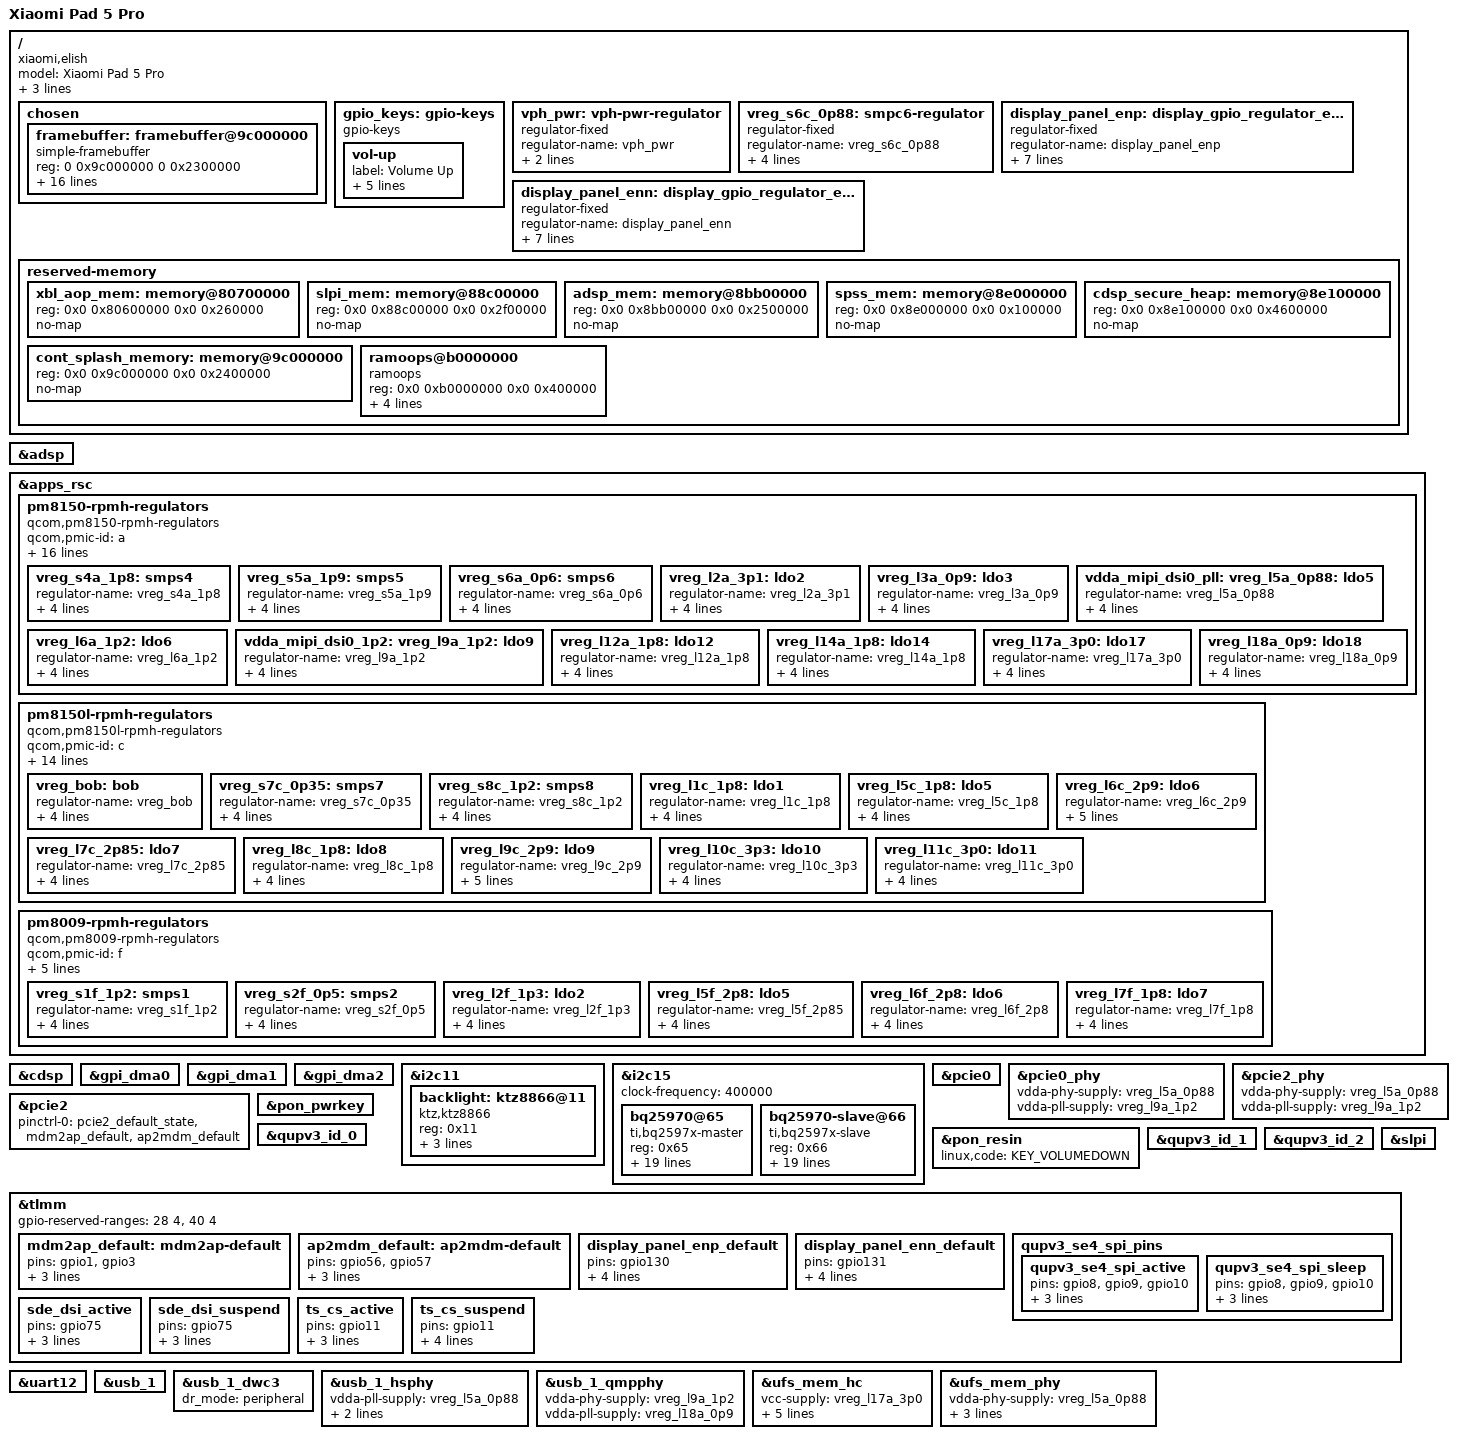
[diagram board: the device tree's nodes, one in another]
// SPDX-License-Identifier: BSD-3-Clause
/*
 * Copyright (c) 2020, The Linux Foundation. All rights reserved.
 */

/dts-v1/;

#include <dt-bindings/regulator/qcom,rpmh-regulator.h>
#include <dt-bindings/gpio/gpio.h>
#include "sm8250.dtsi"
#include "pm8150.dtsi"
#include "pm8150b.dtsi"
#include "pm8150l.dtsi"
#include "pm8009.dtsi"

/*
 * Delete following upstream (sm8250.dtsi) reserved
 * memory mappings which are different in this device.
 */
/delete-node/ &xbl_aop_mem;
/delete-node/ &slpi_mem;
/delete-node/ &adsp_mem;
/delete-node/ &spss_mem;
/delete-node/ &cdsp_secure_heap;

/ {
	model = "Xiaomi Pad 5 Pro";
	compatible = "xiaomi,elish", "qcom,sm8250";
	classis-type = "tablet";

	/* required for bootloader to select correct board */
	qcom,msm-id = <356 0x20001>; /* SM8250 v2.1 */
	qcom,board-id = <0x10008 0>;

	chosen {
		#address-cells = <2>;
		#size-cells = <2>;
		ranges;

		framebuffer: framebuffer@9c000000 {
			compatible = "simple-framebuffer";
			reg = <0 0x9c000000 0 0x2300000>;
			width = <1600>;
			height = <2560>;
			stride = <(1600 * 4)>;
			format = "a8r8g8b8";
			enp-supply = <&display_panel_enp>;
			enn-supply = <&display_panel_enn>;
			/*
			 * That's a lot of clocks, but it's necessary due
			 * to unused clk cleanup & no panel driver yet..
			 */
			clocks = <&dispcc DISP_CC_MDSS_AHB_CLK>,
				 <&gcc GCC_DISP_HF_AXI_CLK>,
				 <&gcc GCC_DISP_SF_AXI_CLK>,
				 <&dispcc DISP_CC_MDSS_VSYNC_CLK>,
				 <&dispcc DISP_CC_MDSS_MDP_CLK>,
				 <&dispcc DISP_CC_MDSS_BYTE0_CLK>,
				 <&dispcc DISP_CC_MDSS_BYTE0_INTF_CLK>,
				 <&dispcc DISP_CC_MDSS_PCLK0_CLK>,
				 <&dispcc DISP_CC_MDSS_ESC0_CLK>;
			power-domains = <&dispcc MDSS_GDSC>;
		};
	};

	gpio_keys: gpio-keys {
		compatible = "gpio-keys";

		/*
		 * Camera focus (light press) and camera snapshot (full press)
		 * seem not to work properly.. Adding the former one stalls the CPU
		 * and the latter kills the volume down key for whatever reason. In any
		 * case, they are both on &pm8150b_gpios: camera focus(2), camera snapshot(1).
		 */

		//vol-down {
		//	label = "Volume Down";
		//	linux,code = <KEY_VOLUMEDOWN>;
		//	gpios = <&pm8150_gpios 1 GPIO_ACTIVE_LOW>;
		//	debounce-interval = <15>;
		//	linux,can-disable;
		//	gpio-key,wakeup;
		//};

                vol-up {
			label = "Volume Up";
			gpios = <&pm8150_gpios 6 GPIO_ACTIVE_LOW>;
			linux,code = <KEY_VOLUMEUP>;
			debounce-interval = <15>;
			linux,can-disable;
			gpio-key,wakeup;
		};
	};

	vph_pwr: vph-pwr-regulator {
		compatible = "regulator-fixed";
		regulator-name = "vph_pwr";
		regulator-min-microvolt = <3700000>;
		regulator-max-microvolt = <3700000>;
	};

	/* S6c is really ebi.lvl but it's there for supply map completeness sake. */
	vreg_s6c_0p88: smpc6-regulator {
		compatible = "regulator-fixed";
		regulator-name = "vreg_s6c_0p88";

		regulator-min-microvolt = <880000>;
		regulator-max-microvolt = <880000>;
		regulator-always-on;
		vin-supply = <&vph_pwr>;
	};

	display_panel_enp: display_gpio_regulator_enp {
		compatible = "regulator-fixed";
		regulator-name = "display_panel_enp";

		regulator-min-microvolt = <5500000>;
		regulator-max-microvolt = <5500000>;
		regulator-enable-ramp-delay = <233>;
		gpio = <&tlmm 130 0>;
		enable-active-high;
		regulator-boot-on;
		pinctrl-names = "default";
		pinctrl-0 = <&display_panel_enp_default>;
	};

	display_panel_enn: display_gpio_regulator_enn {
		compatible = "regulator-fixed";
		regulator-name = "display_panel_enn";

		regulator-min-microvolt = <5500000>;
		regulator-max-microvolt = <5500000>;
		regulator-enable-ramp-delay = <233>;
		gpio = <&tlmm 131 0>;
		enable-active-high;
		regulator-boot-on;
		pinctrl-names = "default";
		pinctrl-0 = <&display_panel_enn_default>;
	};

	reserved-memory {
		xbl_aop_mem: memory@80700000 {
			reg = <0x0 0x80600000 0x0 0x260000>;
	    		no-map;
	    	};

		slpi_mem: memory@88c00000 {
			reg = <0x0 0x88c00000 0x0 0x2f00000>;
	    		no-map;
	    	};

		adsp_mem: memory@8bb00000 {
			reg = <0x0 0x8bb00000 0x0 0x2500000>;
	    		no-map;
	    	};

		spss_mem: memory@8e000000 {
			reg = <0x0 0x8e000000 0x0 0x100000>;
	    		no-map;
	    	};

		cdsp_secure_heap: memory@8e100000 {
			reg = <0x0 0x8e100000 0x0 0x4600000>;
	    		no-map;
	    	};

		cont_splash_memory: memory@9c000000 {
	    		reg = <0x0 0x9c000000 0x0 0x2400000>;
			no-map;
	    	};
		
		ramoops@b0000000 {
    			compatible = "ramoops";
			reg = <0x0 0xb0000000 0x0 0x400000>;
			record-size = <0x1000>;
    			pmsg-size = <0x200000>;
    			console-size = <0x200000>;
			no-map;
		};
	};
};

&adsp {
	status = "okay";
};

&apps_rsc {
	pm8150-rpmh-regulators {
		compatible = "qcom,pm8150-rpmh-regulators";
		qcom,pmic-id = "a";

		vdd-s1-supply = <&vph_pwr>;
		vdd-s2-supply = <&vph_pwr>;
		vdd-s3-supply = <&vph_pwr>;
		vdd-s4-supply = <&vph_pwr>;
		vdd-s5-supply = <&vph_pwr>;
		vdd-s6-supply = <&vph_pwr>;
		vdd-s7-supply = <&vph_pwr>;
		vdd-s8-supply = <&vph_pwr>;
		vdd-s9-supply = <&vph_pwr>;
		vdd-s10-supply = <&vph_pwr>;
		vdd-l1-l8-l11-supply = <&vreg_s6c_0p88>;
		vdd-l2-l10-supply = <&vreg_bob>;
		vdd-l3-l4-l5-l18-supply = <&vreg_s6a_0p6>;
		vdd-l6-l9-supply = <&vreg_s8c_1p2>;
		vdd-l7-l12-l14-l15-supply = <&vreg_s5a_1p9>;
		vdd-l13-l16-l17-supply = <&vreg_bob>;

		/* (S1+S2+S3) - cx.lvl (ARC) */

		vreg_s4a_1p8: smps4 {
			regulator-name = "vreg_s4a_1p8";
			regulator-min-microvolt = <1800000>;
			regulator-max-microvolt = <1920000>;
			regulator-initial-mode = <RPMH_REGULATOR_MODE_HPM>;
		};

		vreg_s5a_1p9: smps5 {
			regulator-name = "vreg_s5a_1p9";
			regulator-min-microvolt = <1824000>;
			regulator-max-microvolt = <2040000>;
			regulator-initial-mode = <RPMH_REGULATOR_MODE_HPM>;
		};

		vreg_s6a_0p6: smps6 {
			regulator-name = "vreg_s6a_0p6";
			regulator-min-microvolt = <600000>;
			regulator-max-microvolt = <1128000>;
			regulator-initial-mode = <RPMH_REGULATOR_MODE_HPM>;
		};

		vreg_l2a_3p1: ldo2 {
			regulator-name = "vreg_l2a_3p1";
			regulator-min-microvolt = <3072000>;
			regulator-max-microvolt = <3072000>;
			regulator-initial-mode = <RPMH_REGULATOR_MODE_HPM>;
		};

		vreg_l3a_0p9: ldo3 {
			regulator-name = "vreg_l3a_0p9";
			regulator-min-microvolt = <928000>;
			regulator-max-microvolt = <932000>;
			regulator-initial-mode = <RPMH_REGULATOR_MODE_HPM>;
		};

		/* L4 - lmx.lvl (ARC) */

		vdda_mipi_dsi0_pll:
		vreg_l5a_0p88: ldo5 {
			regulator-name = "vreg_l5a_0p88";
			regulator-min-microvolt = <880000>;
			regulator-max-microvolt = <880000>;
			regulator-initial-mode = <RPMH_REGULATOR_MODE_HPM>;
		};

		vreg_l6a_1p2: ldo6 {
			regulator-name = "vreg_l6a_1p2";
			regulator-min-microvolt = <1200000>;
			regulator-max-microvolt = <1200000>;
			regulator-initial-mode = <RPMH_REGULATOR_MODE_HPM>;
		};

		/* L7 is unused. */

		vdda_mipi_dsi0_1p2:
		vreg_l9a_1p2: ldo9 {
			regulator-name = "vreg_l9a_1p2";
			regulator-min-microvolt = <1200000>;
			regulator-max-microvolt = <1200000>;
			regulator-initial-mode = <RPMH_REGULATOR_MODE_HPM>;
		};

		/* L10 is unused, L11 - lcx.lvl (ARC) */

		vreg_l12a_1p8: ldo12 {
			regulator-name = "vreg_l12a_1p8";
			regulator-min-microvolt = <1800000>;
			regulator-max-microvolt = <1800000>;
			regulator-initial-mode = <RPMH_REGULATOR_MODE_HPM>;
		};

		/* L13 is unused. */

		vreg_l14a_1p8: ldo14 {
			regulator-name = "vreg_l14a_1p8";
			regulator-min-microvolt = <1800000>;
			regulator-max-microvolt = <1880000>;
			regulator-initial-mode = <RPMH_REGULATOR_MODE_HPM>;
		};

		/* L15 & L16 are unused. */

		vreg_l17a_3p0: ldo17 {
			regulator-name = "vreg_l17a_3p0";
			regulator-min-microvolt = <2496000>;
			regulator-max-microvolt = <3008000>;
			regulator-initial-mode = <RPMH_REGULATOR_MODE_HPM>;
		};

		vreg_l18a_0p9: ldo18 {
			regulator-name = "vreg_l18a_0p9";
			regulator-min-microvolt = <800000>;
			regulator-max-microvolt = <920000>;
			regulator-initial-mode = <RPMH_REGULATOR_MODE_HPM>;
		};
	};

	/*
	 * Remaining regulators that are not yet supported:
	 * OLEDB: 4925000-8100000
	 * ab: 4600000-6100000
	 * ibb: 800000-5400000
	 */
	pm8150l-rpmh-regulators {
		compatible = "qcom,pm8150l-rpmh-regulators";
		qcom,pmic-id = "c";

		vdd-s1-supply = <&vph_pwr>;
		vdd-s2-supply = <&vph_pwr>;
		vdd-s3-supply = <&vph_pwr>;
		vdd-s4-supply = <&vph_pwr>;
		vdd-s5-supply = <&vph_pwr>;
		vdd-s6-supply = <&vph_pwr>;
		vdd-s7-supply = <&vph_pwr>;
		vdd-s8-supply = <&vph_pwr>;
		vdd-l1-l8-supply = <&vreg_s4a_1p8>;
		vdd-l2-l3-supply = <&vreg_s8c_1p2>;
		vdd-l4-l5-l6-supply = <&vreg_bob>;
		vdd-l7-l11-supply = <&vreg_bob>;
		vdd-l9-l10-supply = <&vreg_bob>;
		vdd-bob-supply = <&vph_pwr>;

		vreg_bob: bob {
			regulator-name = "vreg_bob";
			regulator-min-microvolt = <3350000>;
			regulator-max-microvolt = <3960000>;
			regulator-initial-mode = <RPMH_REGULATOR_MODE_AUTO>;
		};

		/*
		 * S1-S6 are ARCs:
		 * (S1+S2) - gfx.lvl,
		 * S3 - mx.lvl,
		 * (S4+S5) - mmcx.lvl,
		 * S6 - ebi.lvl
		 */

		vreg_s7c_0p35: smps7 {
			regulator-name = "vreg_s7c_0p35";
			regulator-min-microvolt = <348000>;
			regulator-max-microvolt = <1000000>;
			regulator-initial-mode = <RPMH_REGULATOR_MODE_HPM>;
		};

		vreg_s8c_1p2: smps8 {
			regulator-name = "vreg_s8c_1p2";
			regulator-min-microvolt = <1200000>;
			regulator-max-microvolt = <1400000>;
			regulator-initial-mode = <RPMH_REGULATOR_MODE_HPM>;
		};

		vreg_l1c_1p8: ldo1 {
			regulator-name = "vreg_l1c_1p8";
			regulator-min-microvolt = <1800000>;
			regulator-max-microvolt = <1800000>;
			regulator-initial-mode = <RPMH_REGULATOR_MODE_HPM>;
		};

		/* L2-4 are unused. */

		vreg_l5c_1p8: ldo5 {
			regulator-name = "vreg_l5c_1p8";
			regulator-min-microvolt = <1800000>;
			regulator-max-microvolt = <2800000>;
			regulator-initial-mode = <RPMH_REGULATOR_MODE_HPM>;
		};

		vreg_l6c_2p9: ldo6 {
			regulator-name = "vreg_l6c_2p9";
			regulator-min-microvolt = <1800000>;
			regulator-max-microvolt = <2960000>;
			regulator-initial-mode = <RPMH_REGULATOR_MODE_HPM>;
			regulator-allow-set-load;
		};

		vreg_l7c_2p85: ldo7 {
			regulator-name = "vreg_l7c_2p85";
			regulator-min-microvolt = <2856000>;
			regulator-max-microvolt = <3104000>;
			regulator-initial-mode = <RPMH_REGULATOR_MODE_HPM>;
		};

		vreg_l8c_1p8: ldo8 {
			regulator-name = "vreg_l8c_1p8";
			regulator-min-microvolt = <1800000>;
			regulator-max-microvolt = <1800000>;
			regulator-initial-mode = <RPMH_REGULATOR_MODE_HPM>;
		};

		vreg_l9c_2p9: ldo9 {
			regulator-name = "vreg_l9c_2p9";
			regulator-min-microvolt = <2704000>;
			regulator-max-microvolt = <2960000>;
			regulator-initial-mode = <RPMH_REGULATOR_MODE_HPM>;
			regulator-allow-set-load;
		};

		vreg_l10c_3p3: ldo10 {
			regulator-name = "vreg_l10c_3p3";
			regulator-min-microvolt = <3296000>;
			regulator-max-microvolt = <3296000>;
			regulator-initial-mode = <RPMH_REGULATOR_MODE_HPM>;
		};

		vreg_l11c_3p0: ldo11 {
			regulator-name = "vreg_l11c_3p0";
			regulator-min-microvolt = <3000000>;
			regulator-max-microvolt = <3000000>;
			regulator-initial-mode = <RPMH_REGULATOR_MODE_HPM>;
		};
	};

	pm8009-rpmh-regulators {
		compatible = "qcom,pm8009-rpmh-regulators";
		qcom,pmic-id = "f";

		vdd-s1-supply = <&vph_pwr>;
		vdd-s2-supply = <&vreg_bob>;
		vdd-l2-supply = <&vreg_s8c_1p2>;
		vdd-l5-l6-supply = <&vreg_bob>;
		vdd-l7-supply = <&vreg_s4a_1p8>;

		vreg_s1f_1p2: smps1 {
			regulator-name = "vreg_s1f_1p2";
			regulator-min-microvolt = <1200000>;
			regulator-max-microvolt = <1200000>;
			regulator-initial-mode = <RPMH_REGULATOR_MODE_HPM>;
		};

		vreg_s2f_0p5: smps2 {
			regulator-name = "vreg_s2f_0p5";
			regulator-min-microvolt = <512000>;
			regulator-max-microvolt = <1100000>;
			regulator-initial-mode = <RPMH_REGULATOR_MODE_HPM>;
		};

		/* L1 is unused. */

		vreg_l2f_1p3: ldo2 {
			regulator-name = "vreg_l2f_1p3";
			regulator-min-microvolt = <1304000>;
			regulator-max-microvolt = <1304000>;
			regulator-initial-mode = <RPMH_REGULATOR_MODE_HPM>;
		};

		/* L3 & L4 are unused. */

		vreg_l5f_2p8: ldo5 {
			regulator-name = "vreg_l5f_2p85";
			regulator-min-microvolt = <2800000>;
			regulator-max-microvolt = <2800000>;
			regulator-initial-mode = <RPMH_REGULATOR_MODE_HPM>;
		};

		vreg_l6f_2p8: ldo6 {
			regulator-name = "vreg_l6f_2p8";
			regulator-min-microvolt = <2800000>;
			regulator-max-microvolt = <2800000>;
			regulator-initial-mode = <RPMH_REGULATOR_MODE_HPM>;
		};

		vreg_l7f_1p8: ldo7 {
			regulator-name = "vreg_l7f_1p8";
			regulator-min-microvolt = <1800000>;
			regulator-max-microvolt = <1800000>;
			regulator-initial-mode = <RPMH_REGULATOR_MODE_HPM>;
		};
	};
};

&cdsp {
	status = "okay";
};

&gpi_dma0 {
	status = "okay";
};

&gpi_dma1 {
	status = "okay";
};

&gpi_dma2 {
	status = "okay";
};

&i2c11 {
	status = "okay";
	backlight: ktz8866@11 {
		compatible = "ktz,ktz8866";
		status = "ok";
		reg = <0x11>;
		ktz8866,hwen-gpio = <&tlmm 139 0x00>;
		ktz8866,enp-gpio = <&tlmm 130 0x00>;
		ktz8866,enn-gpio = <&tlmm 131 0x00>;
	};
};

//&spi4 {
//	status = "okay";
//  pinctrl-names = "default", "sleep";
//  pinctrl-0 = <&qupv3_se4_spi_active>;
//	pinctrl-1 = <&qupv3_se4_spi_sleep>;
//
//	touchscreen@0 {
//		compatible = "novatek,NVT-ts-spi";
//    spi-max-frequency = <19200000>;
//		reg = <0x0>;
//
//		pinctrl-0 = <&ts_cs_active>;
//		pinctrl-1 = <&ts_cs_suspend>;
//    pinctrl-names = "pmx_ts_active", "pmx_ts_suspend";
//
//    novatek,irq-gpio = <&tlmm 39 0x2001>;
//
//    /*  523 */
//		novatek,swrst-n8-addr = <0x03F0FE>;
//		novatek,spi-rd-fast-addr = <0x03F310>;
//
//    /* MP */
//		novatek,mp-support-dt;
//	};
//};

&i2c15 {
	status = "okay";
	clock-frequency = <400000>;
	bq25970@65 {
		compatible = "ti,bq2597x-master";
		reg = <0x65>;
		//interrupt-parent = <&tlmm>;
		//interrupts = <111 0>;
		ti,irq-gpio = <&tlmm 111 0>;													
		ti,bq2597x,bat-therm-disable;	
		ti,bq2597x,bus-therm-disable;	
		ti,bq2597x,die-therm-disable;	

		ti,bq2597x,bat-ovp-threshold = <4525>;
		ti,bq2597x,bat-ovp-alarm-threshold = <4500>;
		ti,bq2597x,bat-ocp-threshold = <8000>;
		ti,bq2597x,bat-ocp-alarm-threshold = <7500>;
		//for dual cp :
		ti,bq2597x,bat-ocp-disable;

		ti,bq2597x,bus-ovp-threshold = <12000>;
		ti,bq2597x,bus-ovp-alarm-threshold = <11000>;
		ti,bq2597x,bus-ocp-threshold = <3750>;
		ti,bq2597x,bus-ocp-alarm-threshold = <3500>;

		ti,bq2597x,bat-ucp-alarm-threshold = <2000>;

		ti,bq2597x,bat-therm-threshold = <0x15>;/*4.1%*/
		ti,bq2597x,bus-therm-threshold = <0x15>;/*4.1%*/
		ti,bq2597x,die-therm-threshold = <125>;

		ti,bq2597x,ac-ovp-threshold = <12>;
		ti,bq2597x,sense-resistor-mohm = <2>;
	};
	bq25970-slave@66 {
		compatible = "ti,bq2597x-slave";
		//compatible = "ti,bq2597x-standalone";
		reg = <0x66>;
		//interrupt-parent = <&tlmm>;
		//interrupts = <7 0>;
		ti,irq-gpio = <&tlmm 7 0>;													
		ti,bq2597x,bat-therm-disable;	
		ti,bq2597x,bus-therm-disable;	
		ti,bq2597x,die-therm-disable;	

		ti,bq2597x,bat-ovp-threshold = <4525>;
		ti,bq2597x,bat-ovp-alarm-threshold = <4500>;
		ti,bq2597x,bat-ocp-threshold = <8000>;
		ti,bq2597x,bat-ocp-alarm-threshold = <7500>;
		//for dual cp :
		ti,bq2597x,bat-ocp-disable;

		ti,bq2597x,bus-ovp-threshold = <12000>;
		ti,bq2597x,bus-ovp-alarm-threshold = <11000>;
		ti,bq2597x,bus-ocp-threshold = <3750>;
		ti,bq2597x,bus-ocp-alarm-threshold = <3500>;

		ti,bq2597x,bat-ucp-alarm-threshold = <2000>;

		ti,bq2597x,bat-therm-threshold = <0x15>;/*4.1%*/
		ti,bq2597x,bus-therm-threshold = <0x15>;/*4.1%*/
		ti,bq2597x,die-therm-threshold = <125>;

		ti,bq2597x,ac-ovp-threshold = <12>;
		ti,bq2597x,sense-resistor-mohm = <2>;
	};
};

&pcie0 {
	status = "okay";
};

&pcie0_phy {
	status = "okay";

	vdda-phy-supply = <&vreg_l5a_0p88>;
	vdda-pll-supply = <&vreg_l9a_1p2>;
};

&pcie2 {
	status = "okay";

	pinctrl-0 = <&pcie2_default_state &mdm2ap_default &ap2mdm_default>;
};

&pcie2_phy {
	status = "okay";

	vdda-phy-supply = <&vreg_l5a_0p88>;
	vdda-pll-supply = <&vreg_l9a_1p2>;
};

&pon_pwrkey {
	status = "okay";
};

&pon_resin {
	status = "okay";

	linux,code = <KEY_VOLUMEDOWN>;
};

&qupv3_id_0 {
	status = "okay";
};

&qupv3_id_1 {
	status = "okay";
};

&qupv3_id_2 {
	status = "okay";
};

&slpi {
	status = "okay";
};

&tlmm {
	gpio-reserved-ranges = <28 4>, <40 4>;

	mdm2ap_default: mdm2ap-default {
		pins = "gpio1", "gpio3";
		function = "gpio";
		drive-strength = <8>;
		bias-disable;
	};

	ap2mdm_default: ap2mdm-default {
		pins = "gpio56", "gpio57";
		function = "gpio";
		drive-strength = <16>;
		bias-disable;
	};

	display_panel_enp_default: display_panel_enp_default {
		pins = "gpio130";
		function = "gpio";
		drive-strength = <8>;
		bias-disable = <0>;
		output-high;
	};

	/* GPIO_131 : display_panel_enn -5V */
	display_panel_enn_default: display_panel_enn_default {
		pins = "gpio131";
		function = "gpio";
		drive-strength = <8>;
		bias-disable = <0>;
		output-high;
	};

	qupv3_se4_spi_pins: qupv3_se4_spi_pins {
		qupv3_se4_spi_active: qupv3_se4_spi_active {
			pins = "gpio8", "gpio9", "gpio10";
			function = "qup4";
			drive-strength = <6>;
			bias-disable;
		};

		qupv3_se4_spi_sleep: qupv3_se4_spi_sleep {
			pins = "gpio8", "gpio9", "gpio10";
			function = "gpio";
			drive-strength = <6>;
			bias-disable;
		};
	};

	sde_dsi_active: sde_dsi_active {
		pins = "gpio75";
		function = "gpio";
		drive-strength = <8>;	/* 8 mA */
		bias-disable = <0>;   /* no pull */
	};

	sde_dsi_suspend: sde_dsi_suspend {
		pins = "gpio75";
		function = "gpio";
		drive-strength = <2>;	/* 2 mA */
		bias-pull-down; 		/* PULL DOWN */
	};

	ts_cs_active: ts_cs_active {
		pins = "gpio11";
		function = "qup4";
		drive-strength = <6>;
		bias-disable;
	};

	ts_cs_suspend: ts_cs_suspend {
		pins = "gpio11";
		function = "gpio";
		drive-strength = <6>;
		bias-pull-down;
		output-low;
	};
};

&uart12 {
	status = "okay";
};

//&gmu {
//	status = "okay";
//};
//
//&gpu {
//	status = "okay";
//
//	//zap-shader {
//	//	memory-region = <&gpu_mem>;
//	//	firmware-name = "qcom/sm8250/xiaomi/a650_zap.mdt";
//	//	firmware-name = "qcom/sm8250/a650_zap.mbn";
//	//};
//};

//&dsi0 {
//	status = "okay";
//	vdda-supply = <&vdda_mipi_dsi0_1p2>;
//	pinctrl-names = "default", "sleep";
//	pinctrl-0 = <&sde_dsi_active>;
//	pinctrl-1 = <&sde_dsi_suspend>;
//	
//	display_panel: panel@0 {
//  		compatible = "csot,nt36523a-2K-display";
//  		reg = <0>;
//  
//		vddio-supply = <&vreg_l14a_1p8>;
//		vddenp-supply = <&display_panel_enp>;
//		vddenn-supply = <&display_panel_enn>;		
//
//		backlight = <&backlight>;
//  
//		reset-gpios = <&tlmm 75 0>;
//  
//		port {
//			panel_in: endpoint {
//				  remote-endpoint = <&dsi0_out>;
//			};
//		};
//	};
//};
//
//&dsi0_out {
//	data-lanes = <0 1 2>;
//	remote-endpoint = <&panel_in>;
//};
//
//&dsi0_phy {
//	status = "okay";
//	vdds-supply = <&vdda_mipi_dsi0_pll>;
//};
//
//&mdss {
//	status = "okay";
//};

&usb_1 {
	status = "okay";
};

&usb_1_dwc3 {
	dr_mode = "peripheral";
};

&usb_1_hsphy {
	status = "okay";

	vdda-pll-supply = <&vreg_l5a_0p88>;
	vdda18-supply = <&vreg_l12a_1p8>;
	vdda33-supply = <&vreg_l2a_3p1>;
};

&usb_1_qmpphy {
	status = "okay";

	vdda-phy-supply = <&vreg_l9a_1p2>;
	vdda-pll-supply = <&vreg_l18a_0p9>;
};

&ufs_mem_hc {
	status = "okay";

	vcc-supply = <&vreg_l17a_3p0>;
	vcc-max-microamp = <800000>;
	vccq-supply = <&vreg_l6a_1p2>;
	vccq-max-microamp = <800000>;
	vccq2-supply = <&vreg_s4a_1p8>;
	vccq2-max-microamp = <800000>;
};

&ufs_mem_phy {
	status = "okay";

	vdda-phy-supply = <&vreg_l5a_0p88>;
	vdda-phy-max-microamp = <89900>;
	vdda-pll-supply = <&vreg_l9a_1p2>;
	vdda-pull-max-microamp = <18800>;
};
